# DMPAC0_PAR_PAR_SDE_S_VBUSP_MMR_VBUSP_MMR register map
Vendor: Texas Instruments
Peripheral module from a debugger description file (folder J7ES).
Registers are 32-bit, access per field, reset 0x0 unless marked. A register's access mark holds for its fields unless they carry their own. Offsets are as the file gives them; lines under a group give offsets from that group; [hi:lo] are bit positions; {n}, {i} and the like mark numbered series; 'fields as' and 'values as' point back to an identical list; <NAME> marks a mode.

## DMPAC0_PAR_PAR_SDE_S_VBUSP_MMR_VBUSP_MMR
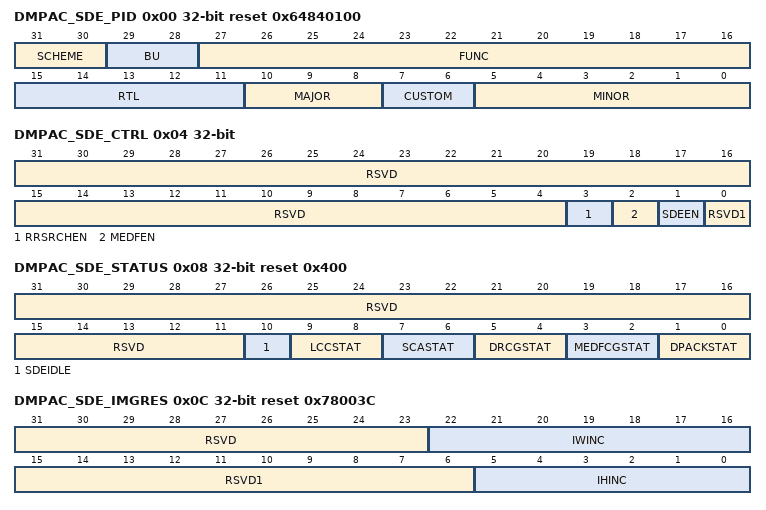
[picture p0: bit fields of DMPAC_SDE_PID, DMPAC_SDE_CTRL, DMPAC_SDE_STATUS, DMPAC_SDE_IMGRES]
0x00 DMPAC_SDE_PID ro reset 0x64840100 — SDE
  [31:30] SCHEME — Used to distinguish between old scheme and new scheme.Spare bit to encode future schemes
  [29:28] BU — BU indicator DSPS ==&gt; 0x0 WTBU ==&gt; 0x1 Processors ==&gt; 0x2
  [27:16] FUNC — Function indicates a software compatible module family.If there is no level of software compatibility a new FUNC number, and hence DMPAC_SDE_PID, should be assigned.
  [15:11] RTL — RTL Version.R as described in PDR with additional clarifications and definitions below. Must be easily ECO-able or controlled during fabrication. Ideally through a top level metal mask or e-fuse. This number is maintained/owned by IP design owner. RTL follows a numbering such as X.Y.R.Z which are explained in this table. R changes ONLY when: (1) PDS uploads occur which may have been due to spec changes (2) Bug fixes occur (3) Resets to '0' when X or Y changes. Design team has an internal 'Z' (customer invisible) number which increments on every drop that happens due to DV and RTL updates. Z resets to 0 when R increments.
  [10:8] MAJOR — Major Revision.X as described in PDR with additional clarifications/definitions below. This number is owned/maintained by IP specification owner. X is part of IP numbering X.Y.R.Z. X changes ONLY when: (1) There is a major feature addition. An example would be adding Master Mode to Utopia Level2. The Func field (or Class/Type in old DMPAC_SDE_PID format) will remain the same. X does NOT change due to: (1) Bug fixes (2) Change in feature parameters.
  [7:6] CUSTOM — Indicates a special version for a particular device.Consequence of use may avoid use of standard Chip Support Library (CSL) / Drivers. 0 if non-custom.
  [5:0] MINOR — Minor Revision.Y as described in PDR with additional clarifications/definitions below. This number is owned/maintained by IP specification owner. Y changes ONLY when: (1) Features are scaled (up or down). Flexibility exists in that this feature scalability may either be represented in the Y change or a specific register in the IP that indicates which features are exactly available. (2) When feature creeps from Is-Not list to Is list. But this may not be the case once it sees silicon - in which case X will change. Y does NOT change due to: (1) Bug fixes (2) Typos or clarifications (3) major functional/feature change/addition/deletion. Instead these changes may be reflected via R, S, X as applicable. Spec owner maintains a customer-invisible number 'S' which changes due to: (1) Typos/clarifications (2) Bug documentation. Note that this bug is not due to a spec change but due to implementation. Nevertheless, the spec tracks the IP bugs. An RTL release (say for silicon PG1.1) that occurs due to bug fix should document the corresponding spec number (X.Y.S) in its release notes.
0x04 DMPAC_SDE_CTRL — SDE control register contains fields that can be used to control DMPAC operation.
  [31:4] RSVD ro — always read as 0.Write has no effect
  [3] RRSRCHEN rw — Enable reduced range search on pixels near right margin where the search range is less than the configured maximum disparity.Write a '1' to enable reduced range search. Default is full range search where disparity is only produced for pixels where a full range search is possible
  [2] MEDFEN rw — Median filter enable.Write a '1' to enable median filter for post processing
  [1] SDEEN rw — SDE enable.Write a '1' to enable DMPAC stereo
  [0] RSVD1 ro — always read as 0.Write has no effect
0x08 DMPAC_SDE_STATUS ro reset 0x400 — SDE register contains fields that return the DMPAC stereo internal .
  [31:11] RSVD — always read as 0.Write has no effect
  [10] SDEIDLE — sdeidle=1 indicate SDE is idle
  [9:8] LCCSTAT — LCC sub-moduleDMPAC_SDE_STATUS: 2'b00: IDLE, 2'b01: ACTIVE, 2'b10: PAUSE, 2'b11: RSVD
  [7:6] SCASTAT — SCA sub-moduleDMPAC_SDE_STATUS: 2'b00: IDLE, 2'b01: ACTIVE, 2'b10: PAUSE, 2'b11: RSVD
  [5:4] DRCGSTAT — DRCG sub-moduleDMPAC_SDE_STATUS: 2'b00: IDLE, 2'b01: ACTIVE, 2'b10: PAUSE, 2'b11: RSVD
  [3:2] MEDFCGSTAT — Median filter sub-moduleDMPAC_SDE_STATUS: 2'b00: IDLE, 2'b01: ACTIVE, 2'b10: PAUSE, 2'b11: RSVD
  [1:0] DPACKSTAT — Disparity packing sub-moduleDMPAC_SDE_STATUS: 2'b00: IDLE, 2'b01: ACTIVE, 2'b10: PAUSE, 2'b11: RSVD
0x0C DMPAC_SDE_IMGRES reset 0x78003C — SDE image resolution register contains fields that can be used to configure input image resolution.
  [31:23] RSVD ro — always read as 0.Write has no effect
  [22:16] IWINC rw — Image width increment factor.Image width iw=128 + 16*iwinc pixels, iwinc=0,1,...,120. Any value greater than 120 will be treated as 120.
  [15:6] RSVD1 ro — always read as 0.Write has no effect
  [5:0] IHINC rw — Image height increment factor.Image height ih=64 + 16*ihinc pixels, ihinc=0,1,...,60. Any value greater than 60 will be treated as 60.
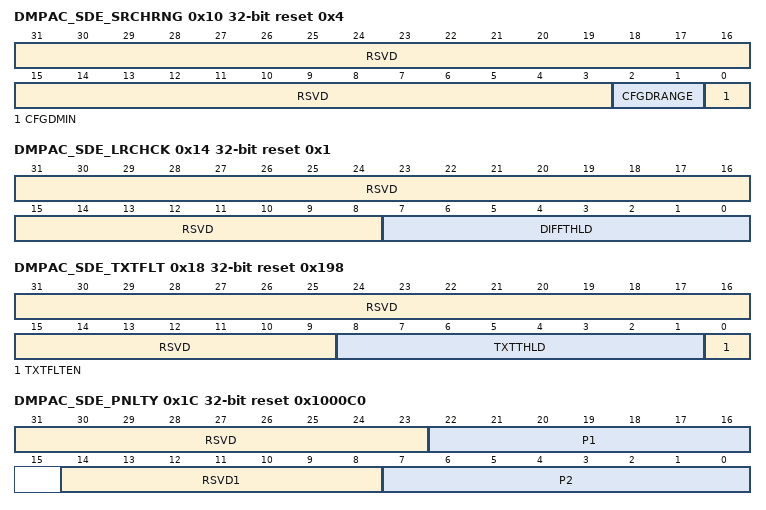
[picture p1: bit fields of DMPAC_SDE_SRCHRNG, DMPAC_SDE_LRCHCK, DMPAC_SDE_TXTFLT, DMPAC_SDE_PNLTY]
0x10 DMPAC_SDE_SRCHRNG reset 0x4 — SDE search range register contains fields that can be used to configure disparity search range.
  [31:3] RSVD ro — always read as 0.Write has no effect
  [2:1] CFGDRANGE rw — Configure disparity search range in pixels.2'b00: search range= 64 (-3 to 60 or 0 to 63), 2'b01:search range=128 (-3 to 124 or 0 to 127), others: search range =192 (-3 to 188 or 0 to 191).
  [0] CFGDMIN rw — Configure minimum disparity (minDisp) to be searched in pixels.0: minDisp=0, 1:minDisp= -3.
0x14 DMPAC_SDE_LRCHCK reset 0x1 — SDE left-right consistence check register contains fields that can be used to configure left-right consistence check.
  [31:8] RSVD ro — always read as 0.Write has no effect
  [7:0] DIFFTHLD rw — Left-right consistence check threshold in pixels.Program diffThld &gt;= maxDisp-minDisp will disable Left-right consistence check.
0x18 DMPAC_SDE_TXTFLT reset 0x198 — SDE texture based filtering control register contains fields that can be used to configure texture based filtering function.
  [31:9] RSVD ro — always read as 0.Write has no effect
  [8:1] TXTTHLD rw — Scaled texture threshold.Any pixel whose texture metric is lower than txtthld is considered to be low texture. It is specified as normalized texture threshold times 1024. For instance, if txtthld = 204, the normalized texture threshold is 204/1024 = 0.1992.
  [0] TXTFLTEN rw — Enable texture based filtering
0x1C DMPAC_SDE_PNLTY reset 0x1000C0 — SDE cost penalty configuration register contains fields that can be used to configure cost penalty function.
  [31:23] RSVD ro — always read as 0.Write has no effect
  [22:16] P1 rw — SDE aggregation penalty P1.Optimization penalty constant for small disparity change.
  [14:8] RSVD1 ro — always read as 0.Write has no effect
  [7:0] P2 rw — SDE aggregation penalty P2.Optimization penalty constant for large disparity change. p2 &lt;= 192. Any value greater than 192 will be treated as 192
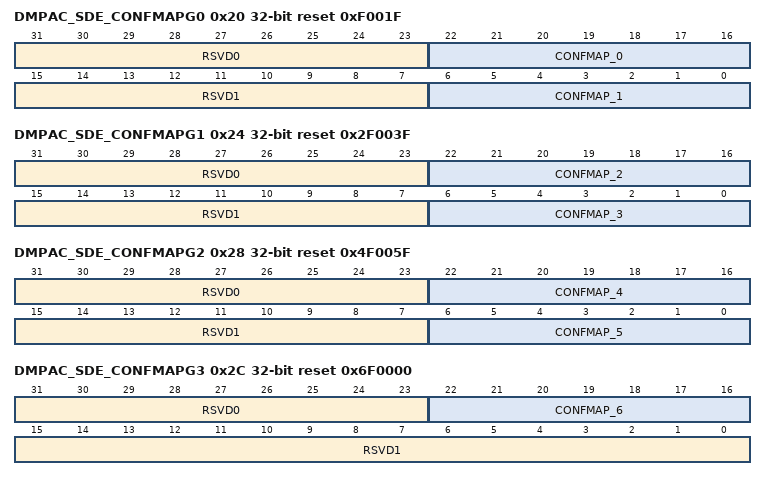
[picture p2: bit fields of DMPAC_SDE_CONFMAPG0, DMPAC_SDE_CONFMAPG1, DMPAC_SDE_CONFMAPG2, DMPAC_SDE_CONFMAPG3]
0x20 DMPAC_SDE_CONFMAPG0 reset 0xF001F — SDE confidence score mapping configuration register 0 specifies level 0 and 1 mapping threshold.
  [31:23] RSVD0 ro — always read as 0.Write has no effect
  [22:16] CONFMAP_0 rw — SDE confidence score mapping 0.Internal confidence score will map to level 0 (of 8 level output) if it is less than confmap_0
  [15:7] RSVD1 ro — always read as 0.Write has no effect
  [6:0] CONFMAP_1 rw — SDE confidence score mapping 1.Internal confidence score will map to level 1 if it is less than confmap_1 but greater than or equal to confmap_0
0x24 DMPAC_SDE_CONFMAPG1 reset 0x2F003F — SDE confidence score mapping configuration register 1 specifies level 2 and 3 mapping threshold.
  [31:23] RSVD0 ro — always read as 0.Write has no effect
  [22:16] CONFMAP_2 rw — SDE confidence score mapping 2.Internal confidence score will map to level 2 if it is less than confmap_2 but greater than or equal to confmap_1
  [15:7] RSVD1 ro — always read as 0.Write has no effect
  [6:0] CONFMAP_3 rw — SDE confidence score mapping 3.Internal confidence score will map to level 3 if it is less than confmap_3 but greater than or equal to confmap_2
0x28 DMPAC_SDE_CONFMAPG2 reset 0x4F005F — SDE confidence score mapping configuration register 2 specifies level 4 and 5 mapping threshold.
  [31:23] RSVD0 ro — always read as 0.Write has no effect
  [22:16] CONFMAP_4 rw — SDE confidence score mapping 4.Internal confidence score will map to level 4 if it is less than confmap_4 but greater than or equal to confmap_3
  [15:7] RSVD1 ro — always read as 0.Write has no effect
  [6:0] CONFMAP_5 rw — SDE confidence score mapping 5.Internal confidence score will map to level 5 if it is less than confmap_5 but greater than or equal to confmap_4
0x2C DMPAC_SDE_CONFMAPG3 reset 0x6F0000 — SDE confidence score mapping configuration register 3 specifies level 6 and 7 mapping threshold.
  [31:23] RSVD0 ro — always read as 0.Write has no effect
  [22:16] CONFMAP_6 rw — SDE confidence score mapping 6.Internal confidence score will map to level 6 if it is less than confmap_6 but greater than or equal to confmap_5
  [15:0] RSVD1 ro — always read as 0.Write has no effect
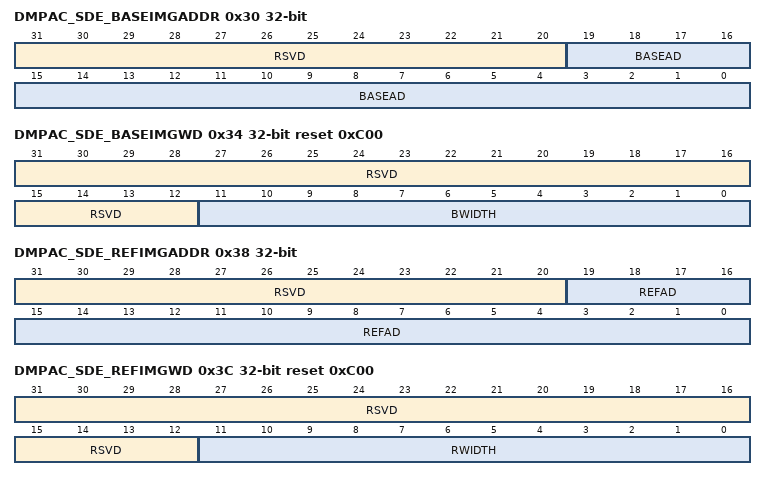
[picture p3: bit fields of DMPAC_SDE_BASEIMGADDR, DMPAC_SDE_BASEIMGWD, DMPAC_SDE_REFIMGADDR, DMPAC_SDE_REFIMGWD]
0x30 DMPAC_SDE_BASEIMGADDR — SDE base image buffer start address register specifies the base image buffer start address in SL2.
  [31:20] RSVD ro — always read as 0.Write has no effect
  [19:0] BASEAD rw — SL2 base image buffer start address (byte address aligned to 64 byte boundary, basead[5:0] should be programmed as 0).
0x34 DMPAC_SDE_BASEIMGWD reset 0xC00 — SDE base image buffer width register specifies the SL2 base image buffer width (The height is fixed at 24 for growing window).
  [31:12] RSVD ro — always read as 0.Write has no effect
  [11:0] BWIDTH rw — SL2 base image buffer width in bytes.bwidth has to satisfy bwidth &gt;= 1.5iw (image width) and is aligned to 64 byte boundaries (LSB 6 bits are always programmed as 0).
0x38 DMPAC_SDE_REFIMGADDR — SDE reference image buffer start address register specifies the reference image buffer start address in SL2.
  [31:20] RSVD ro — always read as 0.Write has no effect
  [19:0] REFAD rw — SL2 reference image buffer start address (byte address aligned to 64 byte boundary, refad[5:0] should be programmed as 0).
0x3C DMPAC_SDE_REFIMGWD reset 0xC00 — SDE reference image buffer width register specifies the SL2 reference image buffer width (The height is fixed at 24 for growing window).
  [31:12] RSVD ro — always read as 0.Write has no effect
  [11:0] RWIDTH rw — SL2 reference image buffer width in bytes.rwidth has to satisfy rwidth &gt;= 1.5*iw (image width) and is aligned to 64 byte boundaries (LSB 6 bits are always programmed as 0).
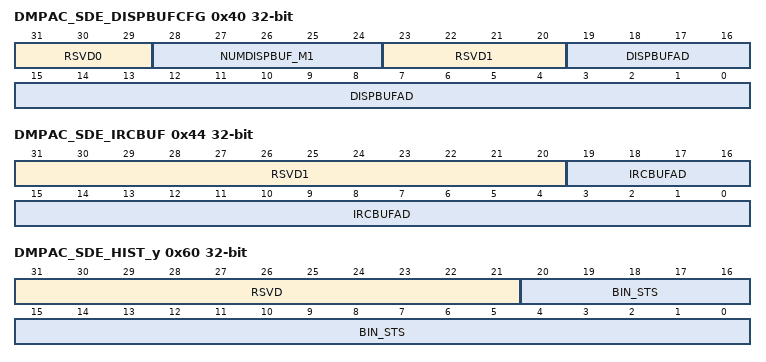
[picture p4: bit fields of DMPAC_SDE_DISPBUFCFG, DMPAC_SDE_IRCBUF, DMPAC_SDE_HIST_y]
0x40 DMPAC_SDE_DISPBUFCFG — SDE disparity block buffer configuration register specifies the disparity output block buffer start address and number of buffers in SL2.
  [31:29] RSVD0 ro — always read as 0.Write has no effect
  [28:24] NUMDISPBUF_M1 rw — number of SL2 disparity block buffers minus 1.For instance, programming numdispbuf_m1 to 1 makes a ping-pong buffer (number of disparity buffers is 2). When SL2 memory is available, programming numdispbuf_m1 to a larger value allow SDE to process more blocks before getting triggers for the corresponding blocks
  [23:20] RSVD1 ro — always read as 0.Write has no effect
  [19:0] DISPBUFAD rw — SL2 disparity output block buffer start address (byte address aligned to 64 byte boundary, dispbufad[5:0] should be programmed as 0).
0x44 DMPAC_SDE_IRCBUF — SDE image row cost buffer configuration register specifies the image row cost buffer start address in SL2.
  [31:20] RSVD1 ro — always read as 0.Write has no effect
  [19:0] IRCBUFAD rw — SL2 image row cost buffer start address (byte address aligned to 64 byte boundary, ircbufad[5:0] should be programmed as 0).
0x50 DMPAC_SDE_PSA_CTRL — Control register for calculating 32b CRC signature on stereo disparity output
  [0] PSA_EN_CFG rw — Enable calculating 32b CRC signature on 16b stereo disparity and confidence score output
0x54 DMPAC_SDE_PSA_SIGNATURE ro reset 0xFFFFFFFF — 32b CRC signature calculated on stereo disparity output
  [31:0] CRC_STS — 32b CRC signature value as calculated on 16b stereo disparity and confidence score output
0x60 DMPAC_SDE_HIST_y ro — SDE Histogram registers stores the counter value of how many confidence scores (scaled to 7-bits) have fallen into each bin Offset = 00100060h + (y * 4h); where y = 0h to 7Fh
  [31:21] RSVD — Always read as 0.Writes have no effect.
  [20:0] BIN_STS — BIN accumulated counter value.Clear to 0 within a 128 cycle window after hts_sde_init is asserted.
